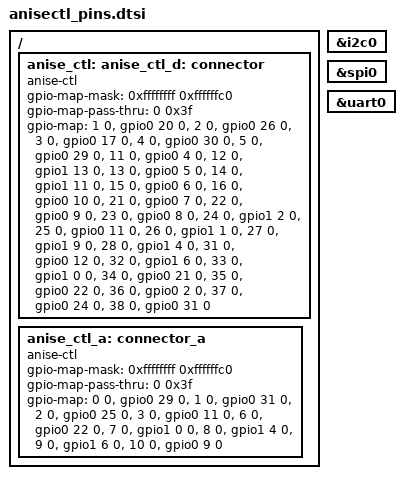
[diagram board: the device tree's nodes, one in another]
/*
 * Copyright (c) 2020 The ZMK Contributors
 *
 * SPDX-License-Identifier: MIT
 */


/ {
	anise_ctl: connector {
		compatible = "anise-ctl";
		#gpio-cells = <2>;
		gpio-map-mask = <0xffffffff 0xffffffc0>;
		gpio-map-pass-thru = <0 0x3f>;
		gpio-map
			= <1 0 &gpio0 20 0>   /**/
			, <2 0 &gpio0 26 0>
			, <3 0 &gpio0 17 0>
			, <4 0 &gpio0 30 0>
			, <5 0 &gpio0 29 0>   /**/
			, <11 0 &gpio0 4 0>   /**/
			, <12 0 &gpio1 13 0>
			, <13 0 &gpio0 5 0>
			, <14 0 &gpio1 11 0>
			, <15 0 &gpio0 6 0>
			, <16 0 &gpio0 10 0>  /**/
			, <21 0 &gpio0 7 0>   /**/
			, <22 0 &gpio0 9 0>
			, <23 0 &gpio0 8 0>
			, <24 0 &gpio1 2 0>
			, <25 0 &gpio0 11 0>
			, <26 0 &gpio1 1 0>
			, <27 0 &gpio1 9 0>
			, <28 0 &gpio1 4 0>   /**/
			, <31 0 &gpio0 12 0>  /**/
			, <32 0 &gpio1 6 0>
			, <33 0 &gpio1 0 0>
			, <34 0 &gpio0 21 0>
			, <35 0 &gpio0 22 0>
			, <36 0 &gpio0 2 0>
			, <37 0 &gpio0 24 0>
			, <38 0 &gpio0 31 0> /**/
			;
	};

	anise_ctl_a: connector_a {
		compatible = "anise-ctl";
		#gpio-cells = <2>;
		gpio-map-mask = <0xffffffff 0xffffffc0>;
		gpio-map-pass-thru = <0 0x3f>;
		gpio-map
			= <0 0 &gpio0 29 0>	/* D18/A0 */
			, <1 0 &gpio0 31 0>	/* D19/A1 */
			, <2 0 &gpio0 25 0>	/* D20/A2 */
			, <3 0 &gpio0 11 0>	/* D21/A3 */
			, <6 0 &gpio0 22 0>	/* D4/A6 */
			, <7 0 &gpio1 0 0>	/* D6/A7 */
			, <8 0 &gpio1 4 0>	/* D8/A8 */
			, <9 0 &gpio1 6 0>	/* D9/A9 */
			, <10 0 &gpio0 9 0>	/* D10/A10 */
			;
	};
};


anise_ctl_d: &anise_ctl {};
anise_ctl_i2c: &i2c0 {};
anise_ctl_spi: &spi0 {};
anise_ctl_serial: &uart0 {};
